# STM32H7x7_CM4 register map
File version: 1.0
CPU: CM4 r0p1, little endian, MPU, FPU, 4 interrupt priority bits
Registers are 32-bit, read-write, reset 0x0 unless marked. A register's access mark holds for its fields unless they carry their own. Offsets are from the block's base; [hi:lo] are bit positions; {n}, {i} and the like mark numbered series.

## SPDIFRX — Receiver Interface
Base 0x40004000
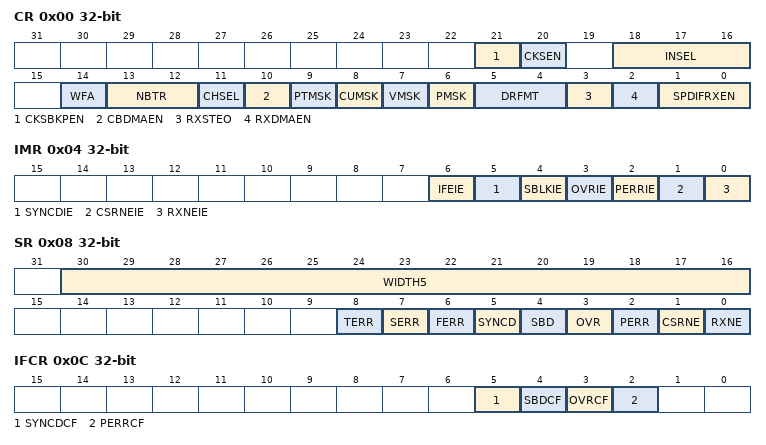
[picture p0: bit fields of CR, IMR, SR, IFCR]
0x00 CR — Control register
  [21] CKSBKPEN — Backup Symbol Clock Enable
  [20] CKSEN — Symbol Clock Enable
  [18:16] INSEL — input selection
  [14] WFA — Wait For Activity
  [13:12] NBTR — Maximum allowed re-tries during synchronization phase
  [11] CHSEL — Channel Selection
  [10] CBDMAEN — Control Buffer DMA ENable for control flow
  [9] PTMSK — Mask of Preamble Type bits
  [8] CUMSK — Mask of channel status and user bits
  [7] VMSK — Mask of Validity bit
  [6] PMSK — Mask Parity error bit
  [5:4] DRFMT — RX Data format
  [3] RXSTEO — STerEO Mode
  [2] RXDMAEN — Receiver DMA ENable for data flow
  [1:0] SPDIFRXEN — Peripheral Block Enable
0x04 IMR — Interrupt mask register
  [6] IFEIE — Serial Interface Error Interrupt Enable
  [5] SYNCDIE — Synchronization Done
  [4] SBLKIE — Synchronization Block Detected Interrupt Enable
  [3] OVRIE — Overrun error Interrupt Enable
  [2] PERRIE — Parity error interrupt enable
  [1] CSRNEIE — Control Buffer Ready Interrupt Enable
  [0] RXNEIE — RXNE interrupt enable
0x08 SR ro — Status register
  [30:16] WIDTH5 — Duration of 5 symbols counted with SPDIF_CLK
  [8] TERR — Time-out error
  [7] SERR — Synchronization error
  [6] FERR — Framing error
  [5] SYNCD — Synchronization Done
  [4] SBD — Synchronization Block Detected
  [3] OVR — Overrun error
  [2] PERR — Parity error
  [1] CSRNE — Control Buffer register is not empty
  [0] RXNE — Read data register not empty
0x0C IFCR wo — Interrupt Flag Clear register
  [5] SYNCDCF — Clears the Synchronization Done flag
  [4] SBDCF — Clears the Synchronization Block Detected flag
  [3] OVRCF — Clears the Overrun error flag
  [2] PERRCF — Clears the Parity error flag
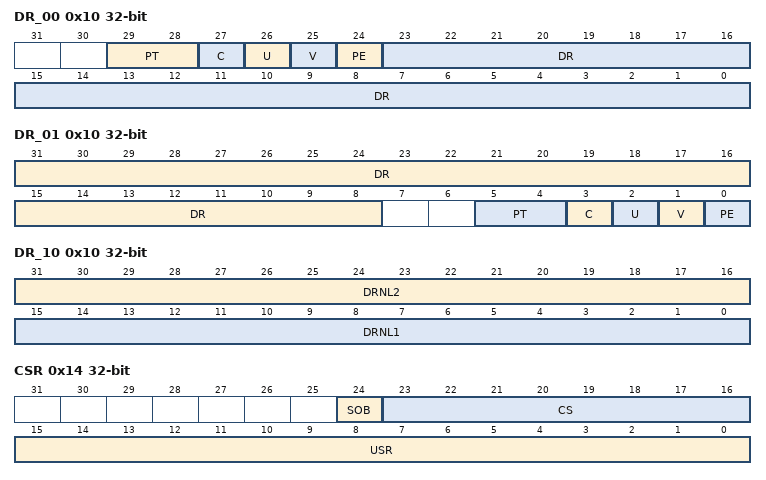
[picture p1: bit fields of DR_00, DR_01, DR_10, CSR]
0x10 DR_00 ro — Data input register
  [29:28] PT — Preamble Type
  [27] C — Channel Status bit
  [26] U — User bit
  [25] V — Validity bit
  [24] PE — Parity Error bit
  [23:0] DR — Parity Error bit
0x10 DR_01 ro (alternate view of DR_00) — Data input register
  [31:8] DR — Data value
  [5:4] PT — Preamble Type
  [3] C — Channel Status bit
  [2] U — User bit
  [1] V — Validity bit
  [0] PE — Parity Error bit
0x10 DR_10 ro (alternate view of DR_00) — Data input register
  [31:16] DRNL2 — Data value
  [15:0] DRNL1 — Data value
0x14 CSR ro — Channel Status register
  [24] SOB — Start Of Block
  [23:16] CS — Channel A status information
  [15:0] USR — User data information
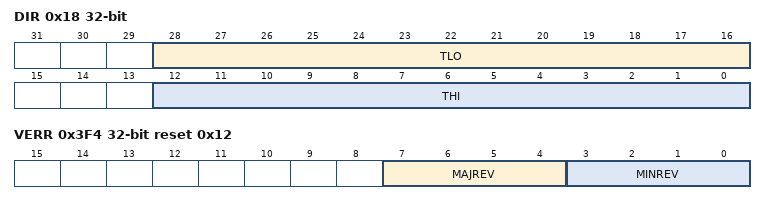
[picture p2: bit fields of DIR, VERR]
0x18 DIR ro — Debug Information register
  [28:16] TLO — Threshold LOW
  [12:0] THI — Threshold HIGH
0x3F4 VERR ro reset 0x12 — SPDIFRX version register
  [7:4] MAJREV — Major revision
  [3:0] MINREV — Minor revision
0x3F8 IDR ro reset 0x130041 — SPDIFRX identification register
  [31:0] ID — SPDIFRX identifier
0x3FC SIDR ro reset 0xA3C5DD01 — SPDIFRX size identification register
  [31:0] SID — Size identification

## DMAMUX1 — DMAMUX
Base 0x40020800
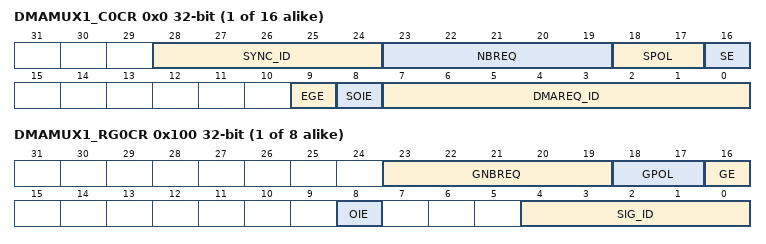
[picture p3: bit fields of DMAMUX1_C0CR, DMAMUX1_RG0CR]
{0x0+4i} DMAMUX1_C{i}CR (i=0..15) — DMAMux - DMA request line multiplexer channel x control register
  [28:24] SYNC_ID — Synchronization input selected
  [23:19] NBREQ — Number of DMA requests to forward Defines the number of DMA requests forwarded before output event is generated. In synchronous mode, it also defines the number of DMA requests to forward after a synchronization event, then stop forwarding. The actual number of DMA requests forwarded is NBREQ+1. Note: This field can only be written when both SE and EGE bits are reset.
  [18:17] SPOL — Synchronization event type selector Defines the synchronization event on the selected synchronization input:
  [16] SE — Synchronous operating mode enable/disable
  [9] EGE — Event generation enable/disable
  [8] SOIE — Interrupt enable at synchronization event overrun
  [7:0] DMAREQ_ID — Input DMA request line selected
0x80 DMAMUX1_CSR ro — DMAMUX request line multiplexer interrupt channel status register
  [15:0] SOF — Synchronization overrun event flag
0x84 DMAMUX1_CFR wo — DMAMUX request line multiplexer interrupt clear flag register
  [15:0] CSOF — Clear synchronization overrun event flag
{0x100+4i} DMAMUX1_RG{i}CR (i=0..7) — DMAMux - DMA request generator channel x control register
  [23:19] GNBREQ — Number of DMA requests to generate Defines the number of DMA requests generated after a trigger event, then stop generating. The actual number of generated DMA requests is GNBREQ+1. Note: This field can only be written when GE bit is reset.
  [18:17] GPOL — DMA request generator trigger event type selection Defines the trigger event on the selected DMA request trigger input
  [16] GE — DMA request generator channel enable/disable
  [8] OIE — Interrupt enable at trigger event overrun
  [4:0] SIG_ID — DMA request trigger input selected
0x140 DMAMUX1_RGSR ro — DMAMux - DMA request generator status register
  [7:0] OF — Trigger event overrun flag The flag is set when a trigger event occurs on DMA request generator channel x, while the DMA request generator counter value is lower than GNBREQ. The flag is cleared by writing 1 to the corresponding COFx bit in DMAMUX_RGCFR register.
0x144 DMAMUX1_RGCFR wo — DMAMux - DMA request generator clear flag register
  [7:0] COF — Clear trigger event overrun flag Upon setting, this bit clears the corresponding overrun flag OFx in the DMAMUX_RGCSR register.
